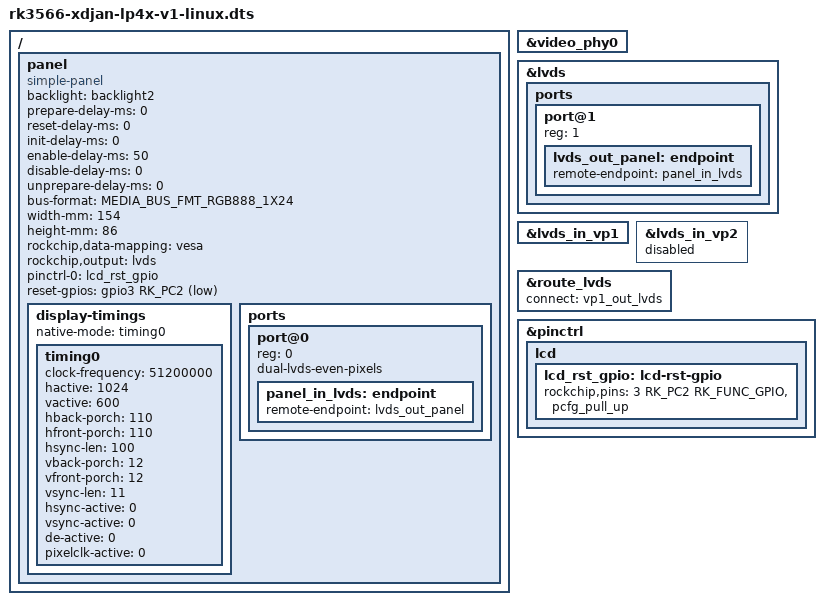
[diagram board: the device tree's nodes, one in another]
// SPDX-License-Identifier: (GPL-2.0+ OR MIT)
/*
 * Copyright (c) 2020 Rockchip Electronics Co., Ltd.
 *
 */

#include <dt-bindings/display/media-bus-format.h>
#include "rk3566-xdjan-lp4x-v1.dtsi"
#include "rk3568-linux.dtsi"

/ {
	panel {
		// LCD for EP169 - Teamworks TC070WS500A0 7inch 1024x600
		compatible = "simple-panel";	//"panel-lvds";
		backlight = <&backlight2>;	//<&backlight>;

		prepare-delay-ms = <0>;
		reset-delay-ms = <0>;
		init-delay-ms = <0>;
		enable-delay-ms = <50>;
		disable-delay-ms = <0>;
		unprepare-delay-ms = <0>;

		bus-format = <MEDIA_BUS_FMT_RGB888_1X24>;	//<MEDIA_BUS_FMT_RGB888_1X7X4_SPWG>;	//<MEDIA_BUS_FMT_RGB666_1X7X3_SPWG>;
		width-mm = <154>;		// 154.2144mm
		height-mm = <86>;		// 85.92mm

		rockchip,data-mapping = "vesa";
		rockchip,output = "lvds";

		pinctrl-names = "default";
		pinctrl-0 = <&lcd_rst_gpio>;
		reset-gpios = <&gpio3 RK_PC2 GPIO_ACTIVE_LOW>;

		status = "okay";

		display-timings {
			native-mode = <&timing0>;

			timing0: timing0 {
				clock-frequency = <51200000>;	//<51206400>;	// 51.2MHz (Frame rate 60Hz)
				hactive = <1024>;
				vactive = <600>;
				hback-porch = <110>;	// HS Blanking 320 (=110+110+100)
				hfront-porch = <110>;
				hsync-len = <100>;
				vback-porch = <12>;	// VS Blanking 35 (=12+12+11)
				vfront-porch = <12>;
				vsync-len = <11>;
				hsync-active = <0>;
				vsync-active = <0>;
				de-active = <0>;	// DE mode only	// <0>; active low  <1>; active high
				pixelclk-active = <0>;
			};
		};

		ports {
			#address-cells = <1>;
			#size-cells = <0>;

			port@0 {
				reg = <0>;
				dual-lvds-even-pixels;
				panel_in_lvds: endpoint {
					remote-endpoint = <&lvds_out_panel>;
				};
			};
		};
	};
};

//&dsi0 {
//	status = "disabled";
//};

//&dsi0_in_vp0 {
//	status = "disabled";
//};

//&dsi0_in_vp1 {
//	status = "disabled";
//};

//&route_dsi0 {
//	status = "disabled";
//	connect = <&vp1_out_dsi0>;
//};

&video_phy0 {
	status = "okay";
};

&lvds {
	status = "okay";

	ports {
		port@1 {
			reg = <1>;

			lvds_out_panel: endpoint {
				remote-endpoint = <&panel_in_lvds>;
			};
		};
	};
};

&lvds_in_vp1 {
	status = "okay";
};

&lvds_in_vp2 {
	status = "disabled";
};

&route_lvds {
	status = "okay";
	connect = <&vp1_out_lvds>;
};

&pinctrl {
	lcd {
		lcd_rst_gpio: lcd-rst-gpio {
			rockchip,pins = <3 RK_PC2 RK_FUNC_GPIO &pcfg_pull_up>;
		};
	};
};
